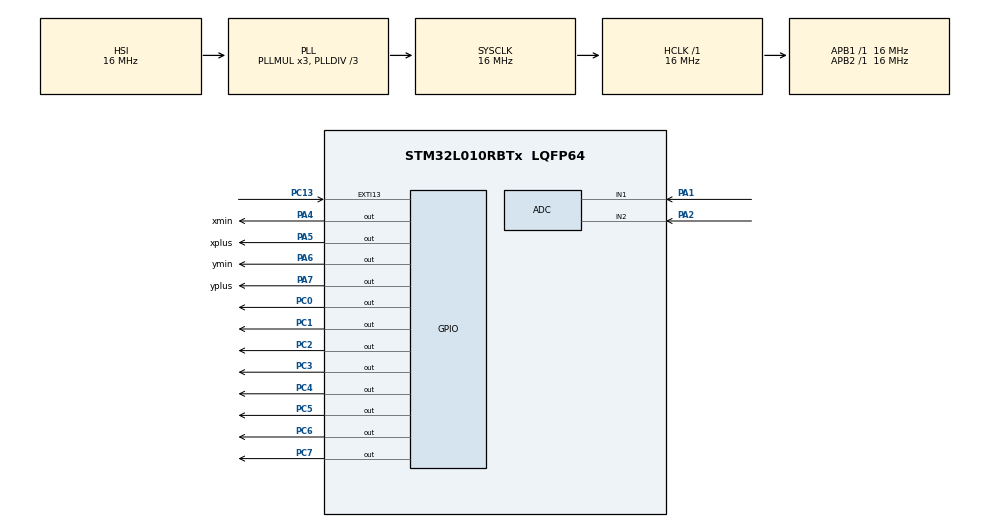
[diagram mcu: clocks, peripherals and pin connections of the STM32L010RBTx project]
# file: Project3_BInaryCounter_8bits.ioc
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ADC.ContinuousConvMode=ENABLE
ADC.EOCSelection=ADC_EOC_SINGLE_CONV
ADC.SamplingTime=ADC_SAMPLETIME_160CYCLES_5
Dma.ADC.0.Direction=DMA_PERIPH_TO_MEMORY
Dma.ADC.0.Instance=DMA1_Channel1
Dma.ADC.0.MemDataAlignment=DMA_MDATAALIGN_WORD
Dma.ADC.0.MemInc=DMA_MINC_ENABLE
Dma.ADC.0.Mode=DMA_CIRCULAR
Dma.ADC.0.PeriphDataAlignment=DMA_PDATAALIGN_WORD
Dma.ADC.0.PeriphInc=DMA_PINC_DISABLE
Dma.ADC.0.Priority=DMA_PRIORITY_LOW
Dma.Request0=ADC
Mcu.Family=STM32L0
Mcu.Name=STM32L010RBTx
Mcu.Package=LQFP64
NVIC.ADC1_IRQn=true\:0\:0\:false\:false\:true\:true\:true
NVIC.DMA1_Channel1_IRQn=true\:0\:0\:false\:false\:true\:false\:true
NVIC.EXTI4_15_IRQn=true\:0\:0\:false\:false\:true\:true\:true
NVIC.RCC_IRQn=true\:0\:0\:false\:false\:true\:true\:false
PA1.Mode=IN1
PA1.Signal=ADC_IN1
PA13.Mode=Serial_Wire
PA13.Signal=SYS_SWDIO
PA14.Mode=Serial_Wire
PA14.Signal=SYS_SWCLK
PA2.Mode=IN2
PA2.Signal=ADC_IN2
PA4.GPIO_Label=xmin
PA4.Signal=GPIO_Output
PA5.GPIO_Label=xplus
PA5.Signal=GPIO_Output
PA6.GPIO_Label=ymin
PA6.Signal=GPIO_Output
PA7.GPIO_Label=yplus
PA7.Signal=GPIO_Output
PC0.PinState=GPIO_PIN_SET
PC0.Signal=GPIO_Output
PC1.PinState=GPIO_PIN_SET
PC1.Signal=GPIO_Output
PC13.Signal=GPXTI13
PC14-OSC32_IN.Mode=LSE-External-Oscillator
PC14-OSC32_IN.Signal=RCC_OSC32_IN
PC15-OSC32_OUT.Mode=LSE-External-Oscillator
PC15-OSC32_OUT.Signal=RCC_OSC32_OUT
PC2.PinState=GPIO_PIN_SET
PC2.Signal=GPIO_Output
PC3.PinState=GPIO_PIN_SET
PC3.Signal=GPIO_Output
PC4.PinState=GPIO_PIN_SET
PC4.Signal=GPIO_Output
PC5.PinState=GPIO_PIN_SET
PC5.Signal=GPIO_Output
PC6.PinState=GPIO_PIN_SET
PC6.Signal=GPIO_Output
PC7.PinState=GPIO_PIN_SET
PC7.Signal=GPIO_Output
PH0-OSC_IN.Mode=HSE-External-Oscillator
PH0-OSC_IN.Signal=RCC_OSC_IN
PH1-OSC_OUT.Mode=HSE-External-Oscillator
PH1-OSC_OUT.Signal=RCC_OSC_OUT
ProjectManager.HeapSize=0x200
ProjectManager.StackSize=0x400
ProjectManager.TargetToolchain=EWARM V8.32
RCC.AHBFreq_Value=16000000
RCC.APB1Freq_Value=16000000
RCC.APB1TimFreq_Value=16000000
RCC.APB2Freq_Value=16000000
RCC.APB2TimFreq_Value=16000000
RCC.HCLKFreq_Value=16000000
RCC.HSE_VALUE=8000000
RCC.HSI16_VALUE=16000000
RCC.HSI48_VALUE=48000000
RCC.HSI_VALUE=16000000
RCC.MSI_VALUE=2097000
RCC.PLLDIV=RCC_PLLDIV_3
RCC.SYSCLKFreq_VALUE=16000000
RCC.SYSCLKSource=RCC_SYSCLKSOURCE_PLLCLK
RCC.VCOOutputFreq_Value=48000000
board=NUCLEO-L010RB

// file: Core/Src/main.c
/* USER CODE BEGIN Header */
/**
  ******************************************************************************
  * @file           : main.c
  * @brief          : Main program body
  ******************************************************************************
  * @attention
  *
  * <h2><center>&copy; Copyright (c) 2021 STMicroelectronics.
  * All rights reserved.</center></h2>
  *
  * This software component is licensed by ST under BSD 3-Clause license,
  * the "License"; You may not use this file except in compliance with the
  * License. You may obtain a copy of the License at:
  *                        opensource.org/licenses/BSD-3-Clause
  *
  ******************************************************************************
  */
/* USER CODE END Header */
#include "main.h"

ADC_HandleTypeDef hadc;
DMA_HandleTypeDef hdma_adc;

void SystemClock_Config(void);
static void MX_GPIO_Init(void);
static void MX_DMA_Init(void);
static void MX_ADC_Init(void);

/* USER CODE BEGIN 0 */
uint32_t VR[2];

/* USER CODE END 0 */

int main(void)
{

  /* MCU Configuration--------------------------------------------------------*/

  /* Reset of all peripherals, Initializes the Flash interface and the Systick. */
  HAL_Init();

  /* Configure the system clock */
  SystemClock_Config();

  /* Initialize all configured peripherals */
  MX_GPIO_Init();
  MX_DMA_Init();
  MX_ADC_Init();
  /* USER CODE BEGIN 2 */
HAL_ADC_Start_DMA(&hadc, VR, 2);
GPIOC->ODR=0;
  /* USER CODE END 2 */

  /* Infinite loop */
  while (1)
  {

  }
}

void SystemClock_Config(void)
{
  RCC_OscInitTypeDef RCC_OscInitStruct = {0};
  RCC_ClkInitTypeDef RCC_ClkInitStruct = {0};

  /** Configure the main internal regulator output voltage
  */
  __HAL_PWR_VOLTAGESCALING_CONFIG(PWR_REGULATOR_VOLTAGE_SCALE1);
  /** Initializes the RCC Oscillators according to the specified parameters
  * in the RCC_OscInitTypeDef structure.
  */
  RCC_OscInitStruct.OscillatorType = RCC_OSCILLATORTYPE_HSI;
  RCC_OscInitStruct.HSIState = RCC_HSI_ON;
  RCC_OscInitStruct.HSICalibrationValue = RCC_HSICALIBRATION_DEFAULT;
  RCC_OscInitStruct.PLL.PLLState = RCC_PLL_ON;
  RCC_OscInitStruct.PLL.PLLSource = RCC_PLLSOURCE_HSI;
  RCC_OscInitStruct.PLL.PLLMUL = RCC_PLLMUL_3;
  RCC_OscInitStruct.PLL.PLLDIV = RCC_PLLDIV_3;
  if (HAL_RCC_OscConfig(&RCC_OscInitStruct) != HAL_OK)
  {
    Error_Handler();
  }
  /** Initializes the CPU, AHB and APB buses clocks
  */
  RCC_ClkInitStruct.ClockType = RCC_CLOCKTYPE_HCLK|RCC_CLOCKTYPE_SYSCLK
                              |RCC_CLOCKTYPE_PCLK1|RCC_CLOCKTYPE_PCLK2;
  RCC_ClkInitStruct.SYSCLKSource = RCC_SYSCLKSOURCE_PLLCLK;
  RCC_ClkInitStruct.AHBCLKDivider = RCC_SYSCLK_DIV1;
  RCC_ClkInitStruct.APB1CLKDivider = RCC_HCLK_DIV1;
  RCC_ClkInitStruct.APB2CLKDivider = RCC_HCLK_DIV1;

  if (HAL_RCC_ClockConfig(&RCC_ClkInitStruct, FLASH_LATENCY_0) != HAL_OK)
  {
    Error_Handler();
  }
}

static void MX_ADC_Init(void)
{

  ADC_ChannelConfTypeDef sConfig = {0};

  /** Configure the global features of the ADC (Clock, Resolution, Data Alignment and number of conversion)
  */
  hadc.Instance = ADC1;
  hadc.Init.OversamplingMode = DISABLE;
  hadc.Init.ClockPrescaler = ADC_CLOCK_SYNC_PCLK_DIV1;
  hadc.Init.Resolution = ADC_RESOLUTION_12B;
  hadc.Init.SamplingTime = ADC_SAMPLETIME_160CYCLES_5;
  hadc.Init.ScanConvMode = ADC_SCAN_DIRECTION_FORWARD;
  hadc.Init.DataAlign = ADC_DATAALIGN_RIGHT;
  hadc.Init.ContinuousConvMode = ENABLE;
  hadc.Init.DiscontinuousConvMode = DISABLE;
  hadc.Init.ExternalTrigConvEdge = ADC_EXTERNALTRIGCONVEDGE_NONE;
  hadc.Init.ExternalTrigConv = ADC_SOFTWARE_START;
  hadc.Init.DMAContinuousRequests = DISABLE;
  hadc.Init.EOCSelection = ADC_EOC_SINGLE_CONV;
  hadc.Init.Overrun = ADC_OVR_DATA_PRESERVED;
  hadc.Init.LowPowerAutoWait = DISABLE;
  hadc.Init.LowPowerFrequencyMode = DISABLE;
  hadc.Init.LowPowerAutoPowerOff = DISABLE;
  if (HAL_ADC_Init(&hadc) != HAL_OK)
  {
    Error_Handler();
  }
  /** Configure for the selected ADC regular channel to be converted.
  */
  sConfig.Channel = ADC_CHANNEL_1;
  sConfig.Rank = ADC_RANK_CHANNEL_NUMBER;
  if (HAL_ADC_ConfigChannel(&hadc, &sConfig) != HAL_OK)
  {
    Error_Handler();
  }
  /** Configure for the selected ADC regular channel to be converted.
  */
  sConfig.Channel = ADC_CHANNEL_2;
  if (HAL_ADC_ConfigChannel(&hadc, &sConfig) != HAL_OK)
  {
    Error_Handler();
  }

}

static void MX_DMA_Init(void)
{

  /* DMA controller clock enable */
  __HAL_RCC_DMA1_CLK_ENABLE();

  /* DMA interrupt init */
  /* DMA1_Channel1_IRQn interrupt configuration */
  HAL_NVIC_SetPriority(DMA1_Channel1_IRQn, 0, 0);
  HAL_NVIC_EnableIRQ(DMA1_Channel1_IRQn);

}

static void MX_GPIO_Init(void)
{
  GPIO_InitTypeDef GPIO_InitStruct = {0};

  /* GPIO Ports Clock Enable */
  __HAL_RCC_GPIOC_CLK_ENABLE();
  __HAL_RCC_GPIOH_CLK_ENABLE();
  __HAL_RCC_GPIOA_CLK_ENABLE();

  /*Configure GPIO pin Output Level */
  HAL_GPIO_WritePin(GPIOC, GPIO_PIN_0|GPIO_PIN_1|GPIO_PIN_2|GPIO_PIN_3
                          |GPIO_PIN_4|GPIO_PIN_5|GPIO_PIN_6|GPIO_PIN_7, GPIO_PIN_SET);

  /*Configure GPIO pin Output Level */
  HAL_GPIO_WritePin(GPIOA, xmin_Pin|xplus_Pin|ymin_Pin|yplus_Pin, GPIO_PIN_RESET);

  /*Configure GPIO pin : PC13 */
  GPIO_InitStruct.Pin = GPIO_PIN_13;
  GPIO_InitStruct.Mode = GPIO_MODE_IT_RISING;
  GPIO_InitStruct.Pull = GPIO_NOPULL;
  HAL_GPIO_Init(GPIOC, &GPIO_InitStruct);

  /*Configure GPIO pins : PC0 PC1 PC2 PC3
                           PC4 PC5 PC6 PC7 */
  GPIO_InitStruct.Pin = GPIO_PIN_0|GPIO_PIN_1|GPIO_PIN_2|GPIO_PIN_3
                          |GPIO_PIN_4|GPIO_PIN_5|GPIO_PIN_6|GPIO_PIN_7;
  GPIO_InitStruct.Mode = GPIO_MODE_OUTPUT_PP;
  GPIO_InitStruct.Pull = GPIO_NOPULL;
  GPIO_InitStruct.Speed = GPIO_SPEED_FREQ_LOW;
  HAL_GPIO_Init(GPIOC, &GPIO_InitStruct);

  /*Configure GPIO pins : xmin_Pin xplus_Pin ymin_Pin yplus_Pin */
  GPIO_InitStruct.Pin = xmin_Pin|xplus_Pin|ymin_Pin|yplus_Pin;
  GPIO_InitStruct.Mode = GPIO_MODE_OUTPUT_PP;
  GPIO_InitStruct.Pull = GPIO_NOPULL;
  GPIO_InitStruct.Speed = GPIO_SPEED_FREQ_LOW;
  HAL_GPIO_Init(GPIOA, &GPIO_InitStruct);

  /* EXTI interrupt init*/
  HAL_NVIC_SetPriority(EXTI4_15_IRQn, 0, 0);
  HAL_NVIC_EnableIRQ(EXTI4_15_IRQn);

}

void Error_Handler(void)
{
  __disable_irq();
  while (1)
  {
  }
}

/************************ (C) COPYRIGHT STMicroelectronics *****END OF FILE****/
